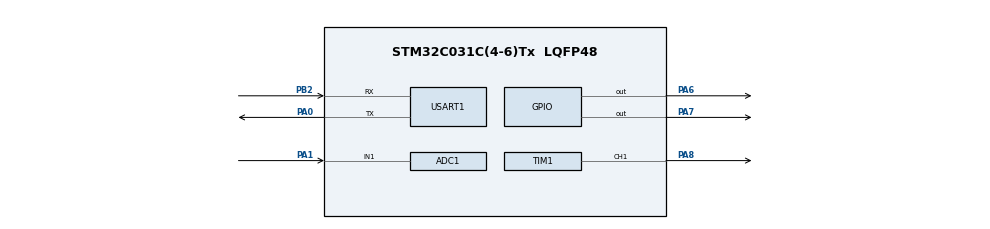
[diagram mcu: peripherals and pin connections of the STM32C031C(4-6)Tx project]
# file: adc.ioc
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ADC1.NbrOfConversionFlag=0
ADC1.SelectedChannel=ADC_CHANNEL_1
ADC1.master=1
Mcu.Family=STM32C0
Mcu.Name=STM32C031C(4-6)Tx
Mcu.Package=LQFP48
NUCLEO-C031C6.BUTTON=1
NUCLEO-C031C6.LD4=true
NUCLEO-C031C6.VCP=true
NVIC.EXTI4_15_IRQn=true\:0\:0\:false\:false\:true\:false\:true\:true
PA0.Mode=Asynchronous
PA0.Signal=USART1_TX
PA1.Mode=IN1
PA1.Signal=ADC1_IN1
PA13.GPIO_Label=DEBUG_SWDIO
PA13.Signal=DEBUG_SWDIO
PA14-BOOT0.GPIO_Label=DEBUG_SWCLK
PA14-BOOT0.Signal=DEBUG_SWCLK
PA2.Signal=USART2_TX
PA3.Signal=USART2_RX
PA6.Signal=GPIO_Output
PA7.Signal=GPIO_Output
PA8.Signal=S_TIM1_CH1
PB2.Mode=Asynchronous
PB2.Signal=USART1_RX
PC14-OSCX_IN\ (PC14).GPIO_Label=RCC_OSCX_IN
PC14-OSCX_IN\ (PC14).Mode=LSE-External-Oscillator
PC14-OSCX_IN\ (PC14).Signal=RCC_OSCX_IN
PC15-OSCX_OUT\ (PC15).GPIO_Label=RCC_OSCX_OUT
PC15-OSCX_OUT\ (PC15).Mode=LSE-External-Oscillator
PC15-OSCX_OUT\ (PC15).Signal=RCC_OSCX_OUT
PF0-OSC_IN\ (PF0).GPIO_Label=RCC_OSC_IN
PF0-OSC_IN\ (PF0).Mode=HSE-External-Oscillator
PF0-OSC_IN\ (PF0).Signal=RCC_OSC_IN
PF1-OSC_OUT\ (PF1).GPIO_Label=RCC_OSC_OUT
PF1-OSC_OUT\ (PF1).Mode=HSE-External-Oscillator
PF1-OSC_OUT\ (PF1).Signal=RCC_OSC_OUT
ProjectManager.HeapSize=0x200
ProjectManager.StackSize=0x400
ProjectManager.TargetToolchain=STM32CubeIDE
RCC.ADCFreq_Value=48000000
RCC.AHBFreq_Value=48000000
RCC.CortexFreq_Value=48000000
RCC.EXTERNAL_CLOCK_VALUE=12288000
RCC.HCLKFreq_Value=48000000
RCC.HSE_VALUE=48000000
RCC.HSISYSCLKDivider=RCC_HSI_DIV1
RCC.HSI_VALUE=48000000
RCC.SYSCLKFreq_VALUE=48000000
RCC.USART1CLockSelection=RCC_USART1CLKSOURCE_SYSCLK
SH.S_TIM1_CH1.0=TIM1_CH1,PWM Generation1 CH1
TIM1.Channel-PWM\ Generation1\ CH1=TIM_CHANNEL_1
TIM1.Period=20000-1
TIM1.Prescaler=48-1
USART1.VirtualMode-Asynchronous=VM_ASYNC
VP_NUCLEO-C031C6_VS_BSP_COMMON.Mode=COMMON
VP_TIM1_VS_ClockSourceINT.Mode=Internal
board=NUCLEO-C031C6

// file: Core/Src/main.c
/* USER CODE BEGIN Header */
/**
  ******************************************************************************
  * @file           : main.c
  * @brief          : Main program body
  ******************************************************************************
  * @attention
  *
  * Copyright (c) 2026 STMicroelectronics.
  * All rights reserved.
  *
  * This software is licensed under terms that can be found in the LICENSE file
  * in the root directory of this software component.
  * If no LICENSE file comes with this software, it is provided AS-IS.
  *
  ******************************************************************************
  */
/* USER CODE END Header */
#include "main.h"

COM_InitTypeDef BspCOMInit;
ADC_HandleTypeDef hadc1;

TIM_HandleTypeDef htim1;

UART_HandleTypeDef huart1;

void SystemClock_Config(void);
static void MX_GPIO_Init(void);
static void MX_ADC1_Init(void);
static void MX_USART1_UART_Init(void);
static void MX_TIM1_Init(void);

int main(void)
{

  /* MCU Configuration--------------------------------------------------------*/

  /* Reset of all peripherals, Initializes the Flash interface and the Systick. */
  HAL_Init();

  /* Configure the system clock */
  SystemClock_Config();

  /* Initialize all configured peripherals */
  MX_GPIO_Init();
  MX_ADC1_Init();
  MX_USART1_UART_Init();
  MX_TIM1_Init();
  /* USER CODE BEGIN 2 */
  HAL_ADCEx_Calibration_Start(&hadc1);
  HAL_TIM_PWM_Start(&htim1, TIM_CHANNEL_1);

  /* USER CODE END 2 */

  /* Initialize leds */
  BSP_LED_Init(LED_GREEN);

  /* Initialize USER push-button, will be used to trigger an interrupt each time it's pressed.*/
  BSP_PB_Init(BUTTON_USER, BUTTON_MODE_EXTI);

  /* Initialize COM1 port (115200, 8 bits (7-bit data + 1 stop bit), no parity */

  /* Infinite loop */
  /* USER CODE BEGIN WHILE */
  while (1)
  {
		HAL_ADC_Start(&hadc1);
		HAL_ADC_PollForConversion(&hadc1, HAL_MAX_DELAY);
		uint32_t adc_val = HAL_ADC_GetValue(&hadc1);
		HAL_ADC_Stop(&hadc1);

		HAL_GPIO_WritePin(GPIOA, GPIO_PIN_6, adc_val > 0 ? GPIO_PIN_SET : GPIO_PIN_RESET);

		uint32_t pulse = 500 + (adc_val * 2000) / 4095;
		__HAL_TIM_SET_COMPARE(&htim1, TIM_CHANNEL_1, pulse);
		HAL_GPIO_WritePin(GPIOA, GPIO_PIN_7, adc_val > 0 ? GPIO_PIN_SET : GPIO_PIN_RESET);

		char msg[32];
		int len = snprintf(msg, sizeof(msg), "ADC: %lu\r\n", adc_val);
		HAL_UART_Transmit(&huart1, (uint8_t*) msg, len, HAL_MAX_DELAY);

		HAL_Delay(200);

    /* USER CODE END WHILE */

  }
}

void SystemClock_Config(void)
{
  RCC_OscInitTypeDef RCC_OscInitStruct = {0};
  RCC_ClkInitTypeDef RCC_ClkInitStruct = {0};

  __HAL_FLASH_SET_LATENCY(FLASH_LATENCY_1);

  /** Initializes the RCC Oscillators according to the specified parameters
  * in the RCC_OscInitTypeDef structure.
  */
  RCC_OscInitStruct.OscillatorType = RCC_OSCILLATORTYPE_HSI;
  RCC_OscInitStruct.HSIState = RCC_HSI_ON;
  RCC_OscInitStruct.HSIDiv = RCC_HSI_DIV1;
  RCC_OscInitStruct.HSICalibrationValue = RCC_HSICALIBRATION_DEFAULT;
  if (HAL_RCC_OscConfig(&RCC_OscInitStruct) != HAL_OK)
  {
    Error_Handler();
  }

  /** Initializes the CPU, AHB and APB buses clocks
  */
  RCC_ClkInitStruct.ClockType = RCC_CLOCKTYPE_HCLK|RCC_CLOCKTYPE_SYSCLK
                              |RCC_CLOCKTYPE_PCLK1;
  RCC_ClkInitStruct.SYSCLKSource = RCC_SYSCLKSOURCE_HSI;
  RCC_ClkInitStruct.SYSCLKDivider = RCC_SYSCLK_DIV1;
  RCC_ClkInitStruct.AHBCLKDivider = RCC_HCLK_DIV1;
  RCC_ClkInitStruct.APB1CLKDivider = RCC_APB1_DIV1;

  if (HAL_RCC_ClockConfig(&RCC_ClkInitStruct, FLASH_LATENCY_1) != HAL_OK)
  {
    Error_Handler();
  }
}

static void MX_ADC1_Init(void)
{

  ADC_ChannelConfTypeDef sConfig = {0};

  /** Configure the global features of the ADC (Clock, Resolution, Data Alignment and number of conversion)
  */
  hadc1.Instance = ADC1;
  hadc1.Init.ClockPrescaler = ADC_CLOCK_SYNC_PCLK_DIV2;
  hadc1.Init.Resolution = ADC_RESOLUTION_12B;
  hadc1.Init.DataAlign = ADC_DATAALIGN_RIGHT;
  hadc1.Init.ScanConvMode = ADC_SCAN_SEQ_FIXED;
  hadc1.Init.EOCSelection = ADC_EOC_SINGLE_CONV;
  hadc1.Init.LowPowerAutoWait = DISABLE;
  hadc1.Init.LowPowerAutoPowerOff = DISABLE;
  hadc1.Init.ContinuousConvMode = DISABLE;
  hadc1.Init.NbrOfConversion = 1;
  hadc1.Init.DiscontinuousConvMode = DISABLE;
  hadc1.Init.ExternalTrigConv = ADC_SOFTWARE_START;
  hadc1.Init.ExternalTrigConvEdge = ADC_EXTERNALTRIGCONVEDGE_NONE;
  hadc1.Init.DMAContinuousRequests = DISABLE;
  hadc1.Init.Overrun = ADC_OVR_DATA_PRESERVED;
  hadc1.Init.SamplingTimeCommon1 = ADC_SAMPLETIME_1CYCLE_5;
  hadc1.Init.OversamplingMode = DISABLE;
  hadc1.Init.TriggerFrequencyMode = ADC_TRIGGER_FREQ_HIGH;
  if (HAL_ADC_Init(&hadc1) != HAL_OK)
  {
    Error_Handler();
  }

  /** Configure Regular Channel
  */
  sConfig.Channel = ADC_CHANNEL_1;
  sConfig.Rank = ADC_RANK_CHANNEL_NUMBER;
  if (HAL_ADC_ConfigChannel(&hadc1, &sConfig) != HAL_OK)
  {
    Error_Handler();
  }

}

static void MX_TIM1_Init(void)
{

  TIM_ClockConfigTypeDef sClockSourceConfig = {0};
  TIM_MasterConfigTypeDef sMasterConfig = {0};
  TIM_OC_InitTypeDef sConfigOC = {0};
  TIM_BreakDeadTimeConfigTypeDef sBreakDeadTimeConfig = {0};

  htim1.Instance = TIM1;
  htim1.Init.Prescaler = 48-1;
  htim1.Init.CounterMode = TIM_COUNTERMODE_UP;
  htim1.Init.Period = 20000-1;
  htim1.Init.ClockDivision = TIM_CLOCKDIVISION_DIV1;
  htim1.Init.RepetitionCounter = 0;
  htim1.Init.AutoReloadPreload = TIM_AUTORELOAD_PRELOAD_DISABLE;
  if (HAL_TIM_Base_Init(&htim1) != HAL_OK)
  {
    Error_Handler();
  }
  sClockSourceConfig.ClockSource = TIM_CLOCKSOURCE_INTERNAL;
  if (HAL_TIM_ConfigClockSource(&htim1, &sClockSourceConfig) != HAL_OK)
  {
    Error_Handler();
  }
  if (HAL_TIM_PWM_Init(&htim1) != HAL_OK)
  {
    Error_Handler();
  }
  sMasterConfig.MasterOutputTrigger = TIM_TRGO_RESET;
  sMasterConfig.MasterOutputTrigger2 = TIM_TRGO2_RESET;
  sMasterConfig.MasterSlaveMode = TIM_MASTERSLAVEMODE_DISABLE;
  if (HAL_TIMEx_MasterConfigSynchronization(&htim1, &sMasterConfig) != HAL_OK)
  {
    Error_Handler();
  }
  sConfigOC.OCMode = TIM_OCMODE_PWM1;
  sConfigOC.Pulse = 0;
  sConfigOC.OCPolarity = TIM_OCPOLARITY_HIGH;
  sConfigOC.OCNPolarity = TIM_OCNPOLARITY_HIGH;
  sConfigOC.OCFastMode = TIM_OCFAST_DISABLE;
  sConfigOC.OCIdleState = TIM_OCIDLESTATE_RESET;
  sConfigOC.OCNIdleState = TIM_OCNIDLESTATE_RESET;
  if (HAL_TIM_PWM_ConfigChannel(&htim1, &sConfigOC, TIM_CHANNEL_1) != HAL_OK)
  {
    Error_Handler();
  }
  sBreakDeadTimeConfig.OffStateRunMode = TIM_OSSR_DISABLE;
  sBreakDeadTimeConfig.OffStateIDLEMode = TIM_OSSI_DISABLE;
  sBreakDeadTimeConfig.LockLevel = TIM_LOCKLEVEL_OFF;
  sBreakDeadTimeConfig.DeadTime = 0;
  sBreakDeadTimeConfig.BreakState = TIM_BREAK_DISABLE;
  sBreakDeadTimeConfig.BreakPolarity = TIM_BREAKPOLARITY_HIGH;
  sBreakDeadTimeConfig.BreakFilter = 0;
  sBreakDeadTimeConfig.BreakAFMode = TIM_BREAK_AFMODE_INPUT;
  sBreakDeadTimeConfig.Break2State = TIM_BREAK2_DISABLE;
  sBreakDeadTimeConfig.Break2Polarity = TIM_BREAK2POLARITY_HIGH;
  sBreakDeadTimeConfig.Break2Filter = 0;
  sBreakDeadTimeConfig.Break2AFMode = TIM_BREAK_AFMODE_INPUT;
  sBreakDeadTimeConfig.AutomaticOutput = TIM_AUTOMATICOUTPUT_DISABLE;
  if (HAL_TIMEx_ConfigBreakDeadTime(&htim1, &sBreakDeadTimeConfig) != HAL_OK)
  {
    Error_Handler();
  }
  HAL_TIM_MspPostInit(&htim1);

}

static void MX_USART1_UART_Init(void)
{

  huart1.Instance = USART1;
  huart1.Init.BaudRate = 115200;
  huart1.Init.WordLength = UART_WORDLENGTH_8B;
  huart1.Init.StopBits = UART_STOPBITS_1;
  huart1.Init.Parity = UART_PARITY_NONE;
  huart1.Init.Mode = UART_MODE_TX_RX;
  huart1.Init.HwFlowCtl = UART_HWCONTROL_NONE;
  huart1.Init.OverSampling = UART_OVERSAMPLING_16;
  huart1.Init.OneBitSampling = UART_ONE_BIT_SAMPLE_DISABLE;
  huart1.Init.ClockPrescaler = UART_PRESCALER_DIV1;
  huart1.AdvancedInit.AdvFeatureInit = UART_ADVFEATURE_NO_INIT;
  if (HAL_UART_Init(&huart1) != HAL_OK)
  {
    Error_Handler();
  }
  if (HAL_UARTEx_SetTxFifoThreshold(&huart1, UART_TXFIFO_THRESHOLD_1_8) != HAL_OK)
  {
    Error_Handler();
  }
  if (HAL_UARTEx_SetRxFifoThreshold(&huart1, UART_RXFIFO_THRESHOLD_1_8) != HAL_OK)
  {
    Error_Handler();
  }
  if (HAL_UARTEx_DisableFifoMode(&huart1) != HAL_OK)
  {
    Error_Handler();
  }

}

static void MX_GPIO_Init(void)
{
  GPIO_InitTypeDef GPIO_InitStruct = {0};

  /* GPIO Ports Clock Enable */
  __HAL_RCC_GPIOC_CLK_ENABLE();
  __HAL_RCC_GPIOF_CLK_ENABLE();
  __HAL_RCC_GPIOA_CLK_ENABLE();
  __HAL_RCC_GPIOB_CLK_ENABLE();

  /*Configure GPIO pin Output Level */
  HAL_GPIO_WritePin(GPIOA, GPIO_PIN_6|GPIO_PIN_7, GPIO_PIN_RESET);

  /*Configure GPIO pins : PA6 PA7 */
  GPIO_InitStruct.Pin = GPIO_PIN_6|GPIO_PIN_7;
  GPIO_InitStruct.Mode = GPIO_MODE_OUTPUT_PP;
  GPIO_InitStruct.Pull = GPIO_NOPULL;
  GPIO_InitStruct.Speed = GPIO_SPEED_FREQ_LOW;
  HAL_GPIO_Init(GPIOA, &GPIO_InitStruct);

}

void Error_Handler(void)
{
  __disable_irq();
  while (1)
  {
  }
}
